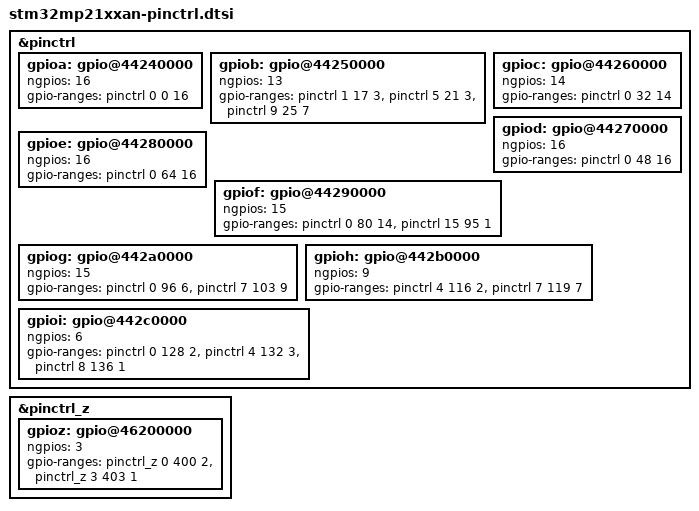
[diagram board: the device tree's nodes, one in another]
// SPDX-License-Identifier: (GPL-2.0-only OR BSD-3-Clause)
/*
 * Copyright (C) STMicroelectronics 2024 - All Rights Reserved
 * Author: Alexandre Torgue <alexandre.torgue@foss.st.com> for STMicroelectronics.
 */

&pinctrl {
	/omit-if-no-ref/
	gpioa: gpio@44240000 {
		status = "okay";
		ngpios = <16>;
		gpio-ranges = <&pinctrl 0 0 16>;
	};

	/omit-if-no-ref/
	gpiob: gpio@44250000 {
		status = "okay";
		ngpios = <13>;
		gpio-ranges = <&pinctrl 1 17 3>, <&pinctrl 5 21 3>, <&pinctrl 9 25 7>;
	};

	/omit-if-no-ref/
	gpioc: gpio@44260000 {
		status = "okay";
		ngpios = <14>;
		gpio-ranges = <&pinctrl 0 32 14>;
	};

	/omit-if-no-ref/
	gpiod: gpio@44270000 {
		status = "okay";
		ngpios = <16>;
		gpio-ranges = <&pinctrl 0 48 16>;
	};

	/omit-if-no-ref/
	gpioe: gpio@44280000 {
		status = "okay";
		ngpios = <16>;
		gpio-ranges = <&pinctrl 0 64 16>;
	};

	/omit-if-no-ref/
	gpiof: gpio@44290000 {
		status = "okay";
		ngpios = <15>;
		gpio-ranges = <&pinctrl 0 80 14>, <&pinctrl 15 95 1>;
	};

	/omit-if-no-ref/
	gpiog: gpio@442a0000 {
		status = "okay";
		ngpios = <15>;
		gpio-ranges = <&pinctrl 0 96 6>, <&pinctrl 7 103 9>;
	};

	/omit-if-no-ref/
	gpioh: gpio@442b0000 {
		status = "okay";
		ngpios = <9>;
		gpio-ranges = <&pinctrl 4 116 2>, <&pinctrl 7 119 7>;
	};

	/omit-if-no-ref/
	gpioi: gpio@442c0000 {
		status = "okay";
		ngpios = <6>;
		gpio-ranges = <&pinctrl 0 128 2>, <&pinctrl 4 132 3>, <&pinctrl 8 136 1>;
	};
};

&pinctrl_z {
	/omit-if-no-ref/
	gpioz: gpio@46200000 {
		status = "okay";
		ngpios = <3>;
		gpio-ranges = <&pinctrl_z 0 400 2>, <&pinctrl_z 3 403 1>;
	};
};
